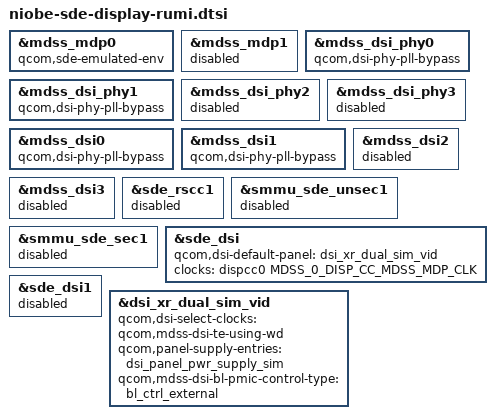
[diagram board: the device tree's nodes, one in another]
#include "niobe-sde-display.dtsi"

&mdss_mdp0 {
	qcom,sde-emulated-env;
};

&mdss_mdp1 {
	status = "disabled";
};

&mdss_dsi_phy0 {
	qcom,dsi-phy-pll-bypass;
};

&mdss_dsi_phy1 {
	qcom,dsi-phy-pll-bypass;
};

&mdss_dsi_phy2 {
	status = "disabled";
};

&mdss_dsi_phy3 {
	status = "disabled";
};

&mdss_dsi0 {
	qcom,dsi-phy-pll-bypass;
};

&mdss_dsi1 {
	qcom,dsi-phy-pll-bypass;
};

&mdss_dsi2 {
	status = "disabled";
};

&mdss_dsi3 {
	status = "disabled";
};

&sde_rscc1 {
	status = "disabled";
};

&smmu_sde_unsec1 {
	status = "disabled";
};

&smmu_sde_sec1 {
	status = "disabled";
};

&sde_dsi {
	qcom,dsi-default-panel = <&dsi_xr_dual_sim_vid>;
	clocks = <&dispcc0 MDSS_0_DISP_CC_MDSS_MDP_CLK>;
	clock-names = "mdp_core_clk";
};

&sde_dsi1 {
	status = "disabled";
};

&dsi_xr_dual_sim_vid {
	/delete-property/ qcom,dsi-select-sec-clocks;

	qcom,dsi-select-clocks = "";
	qcom,mdss-dsi-te-using-wd;
	qcom,panel-supply-entries = <&dsi_panel_pwr_supply_sim>;
	qcom,mdss-dsi-bl-pmic-control-type = "bl_ctrl_external";
};
